# MKW36Z4 register map
Vendor: NXP Semiconductors; Series: Kinetis_W; File version: 1.6
CPU: CM0PLUS r0p0, little endian, no MPU, no FPU, VTOR, 2 interrupt priority bits
Registers are 16-bit, read-write, no defined reset value unless marked. A register's access mark holds for its fields unless they carry their own. Offsets are from the block's base; [hi:lo] are bit positions; {n}, {i} and the like mark numbered series.

## ROM — System ROM
Base 0xF0002000; register names take the prefix ROM_
{0x0+4i} ENTRY{i} (i=0..2) 32-bit ro
  [31:0] ENTRY
0x0C TABLEMARK 32-bit ro reset 0x0 — End of Table Marker Register
  [31:0] MARK
0xFCC SYSACCESS 32-bit ro reset 0x1 — System Access Register
0xFD0 PERIPHID{x} (x=4,5,6,7,0,1,2,3; step 0x4) 32-bit ro — Peripheral ID Register
  [31:0] PERIPHID
{0xFF0+4i} COMPID{i} (i=0..3) 32-bit ro — Component ID Register
  [31:0] COMPID — Component ID

## MCM — Core Platform Miscellaneous Control Module
Base 0xF0003000; register names take the prefix MCM_
0x08 PLASC ro reset 0x7 — Crossbar Switch (AXBS) Slave Configuration
  [7:0] ASC — Each bit in the ASC field indicates whether there is a corresponding connection to the crossbar switch's slave input port.
    0=A bus slave connection to AXBS input port n is absent; 1=A bus slave connection to AXBS input port n is present
0x0A PLAMC ro reset 0x5 — Crossbar Switch (AXBS) Master Configuration
  [7:0] AMC — Each bit in the AMC field indicates whether there is a corresponding connection to the AXBS master input port.
    0=A bus master connection to AXBS input port n is absent; 1=A bus master connection to AXBS input port n is present
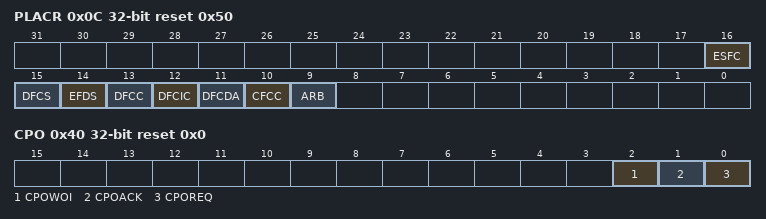
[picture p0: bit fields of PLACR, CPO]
0x0C PLACR 32-bit reset 0x50 — Platform Control Register
  [16] ESFC — Enable Stalling Flash Controller
    0=Disable stalling flash controller when flash is busy; 1=Enable stalling flash controller when flash is busy
  [15] DFCS — Disable Flash Controller Speculation
    0=Enable flash controller speculation; 1=Disable flash controller speculation
  [14] EFDS — Enable Flash Data Speculation
    0=Disable flash data speculation; 1=Enable flash data speculation
  [13] DFCC — Disable Flash Controller Cache
    0=Enable flash controller cache; 1=Disable flash controller cache
  [12] DFCIC — Disable Flash Controller Instruction Caching
    0=Enable flash controller instruction caching; 1=Disable flash controller instruction caching
  [11] DFCDA — Disable Flash Controller Data Caching
    0=Enable flash controller data caching; 1=Disable flash controller data caching
  [10] CFCC wo — Clear Flash Controller Cache
  [9] ARB — Arbitration select
    0=Fixed-priority arbitration for the crossbar masters; 1=Round-robin arbitration for the crossbar masters
0x40 CPO 32-bit reset 0x0 — Compute Operation Control Register
  [2] CPOWOI — Compute Operation Wake-up on Interrupt
    0=No effect; 1=When set, the CPOREQ is cleared on any interrupt or exception vector fetch
  [1] CPOACK ro — Compute Operation Acknowledge
    0=Compute operation entry has not completed or compute operation exit has completed; 1=Compute operation entry has completed or compute operation exit has not completed
  [0] CPOREQ — Compute Operation Request
    0=Request is cleared; 1=Request Compute Operation

## FGPIOA — General Purpose Input/Output
Base 0xF8000000; register names take the prefix FGPIOA_
0x00 PDOR 32-bit reset 0x0 — Port Data Output Register
  [31:0] PDO — Port Data Output
    0=Logic level 0 is driven on pin, provided pin is configured for general-purpose output; 1=Logic level 1 is driven on pin, provided pin is configured for general-purpose output
0x04 PSOR 32-bit wo reset 0x0 — Port Set Output Register
  [31:0] PTSO — Port Set Output
    0=Corresponding bit in PDORn does not change; 1=Corresponding bit in PDORn is set to logic 1
0x08 PCOR 32-bit wo reset 0x0 — Port Clear Output Register
  [31:0] PTCO — Port Clear Output
    0=Corresponding bit in PDORn does not change; 1=Corresponding bit in PDORn is cleared to logic 0
0x0C PTOR 32-bit wo reset 0x0 — Port Toggle Output Register
  [31:0] PTTO — Port Toggle Output
    0=Corresponding bit in PDORn does not change; 1=Corresponding bit in PDORn is set to the inverse of its existing logic state
0x10 PDIR 32-bit ro reset 0x0 — Port Data Input Register
  [31:0] PDI — Port Data Input
    0=Pin logic level is logic 0, or is not configured for use by digital function; 1=Pin logic level is logic 1
0x14 PDDR 32-bit reset 0x0 — Port Data Direction Register
  [31:0] PDD — Port Data Direction
    0=Pin is configured as general-purpose input, for the GPIO function; 1=Pin is configured as general-purpose output, for the GPIO function

## FGPIOB — General Purpose Input/Output
Base 0xF8000040; register names take the prefix FGPIOB_
Registers as FGPIOA.

## FGPIOC — General Purpose Input/Output
Base 0xF8000080; register names take the prefix FGPIOC_
Registers as FGPIOA.
